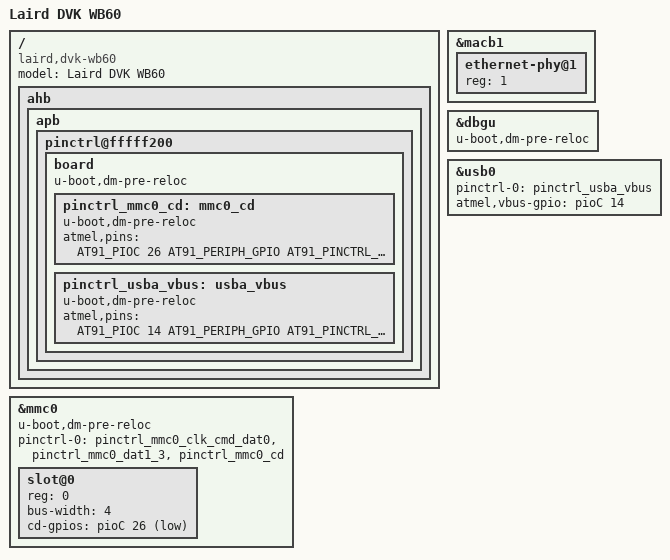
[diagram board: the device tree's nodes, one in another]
/*
 * at91-wb60.dts - Device Tree file for the WB60 module with BB50 DVK
 *
 *  Copyright (C) 2019 Laird,
 *		  2019 Boris Krasnovskiy <boris.krasnovskiy@lairdtech.com>
 *
 * Licensed under GPLv2 or later.
 */

/dts-v1/;

#include "at91-som60.dtsi"

/ {
	model = "Laird DVK WB60";
	compatible = "laird,dvk-wb60", "laird,som60", "atmel,sama5d36", "atmel,sama5d3", "atmel,sama5";

	ahb {
		apb {
			pinctrl@fffff200 {
				board {
					u-boot,dm-pre-reloc;
					pinctrl_mmc0_cd: mmc0_cd {
						u-boot,dm-pre-reloc;
						atmel,pins =
							<AT91_PIOC 26 AT91_PERIPH_GPIO AT91_PINCTRL_DEGLITCH>;
					};

					pinctrl_usba_vbus: usba_vbus {
						u-boot,dm-pre-reloc;
						atmel,pins =
							<AT91_PIOC 14 AT91_PERIPH_GPIO AT91_PINCTRL_DEGLITCH>;
					};
				};
			};
		};
	};
};

&mmc0 {
	u-boot,dm-pre-reloc;
	pinctrl-names = "default";
	pinctrl-0 = <&pinctrl_mmc0_clk_cmd_dat0 &pinctrl_mmc0_dat1_3 &pinctrl_mmc0_cd>;

	status = "okay";

	slot@0 {
		reg = <0>;
		bus-width = <4>;
		cd-gpios = <&pioC 26 GPIO_ACTIVE_LOW>;
	};
};

&macb1 {
	status = "okay";

	ethernet-phy@1 {
		reg = <1>;
	};
};

&dbgu {
	u-boot,dm-pre-reloc;
	status = "okay";
};

&usb0 {
	pinctrl-names = "default";
	pinctrl-0 = <&pinctrl_usba_vbus>;

	atmel,vbus-gpio = <&pioC 14 GPIO_ACTIVE_HIGH>;

	status = "okay";
};
